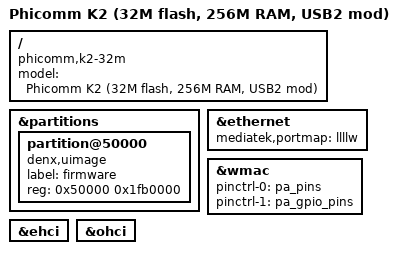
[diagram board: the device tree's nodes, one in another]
// SPDX-License-Identifier: GPL-2.0-or-later

#include "mt7620a_phicomm_k2x.dtsi"

/ {
	compatible = "phicomm,k2-32m", "ralink,mt7620a-soc";
	model = "Phicomm K2 (32M flash, 256M RAM, USB2 mod)";
};

&partitions {
	partition@50000 {
		compatible = "denx,uimage";
		label = "firmware";
		reg = <0x50000 0x1fb0000>;
	};
};

&ethernet {
	mediatek,portmap = "llllw";
};

&wmac {
	pinctrl-names = "default", "pa_gpio";
	pinctrl-0 = <&pa_pins>;
	pinctrl-1 = <&pa_gpio_pins>;
};

/*
 * USB 2.0
 *
 * mt7620a.dtsi 里 ehci / ohci 默认 status = "disabled"，
 * 原厂 K2 无 USB 口所以没启用。硬件改造加了 USB 后需要在此打开。
 */
&ehci {
	status = "okay";
};

&ohci {
	status = "okay";
};
